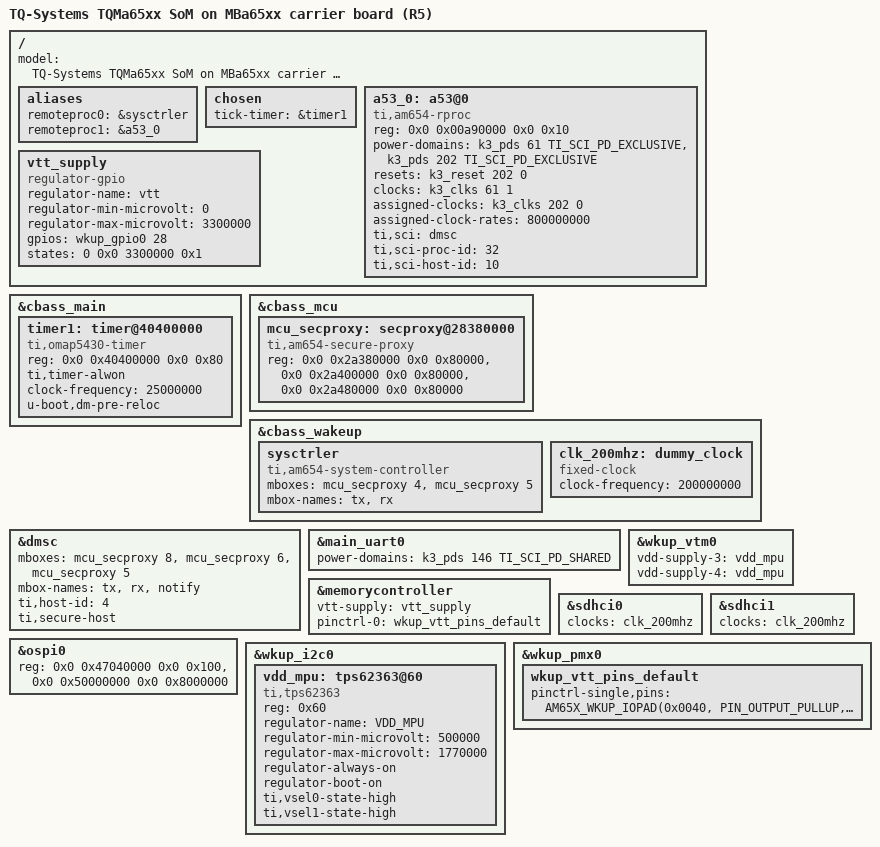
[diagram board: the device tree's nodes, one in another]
// SPDX-License-Identifier: GPL-2.0
/*
 * Copyright (C) 2016-2018 Texas Instruments Incorporated - http://www.ti.com/
 * Copyright (C) 2020-2022 TQ-Systems GmbH
 */

#include "k3-am654-ddr.dtsi"
#include "k3-am654-tqma65xx-mba65xx-u-boot.dtsi"

/ {
	model = "TQ-Systems TQMa65xx SoM on MBa65xx carrier board (R5)";

	aliases {
		remoteproc0 = &sysctrler;
		remoteproc1 = &a53_0;
	};

	chosen {
		tick-timer = &timer1;
	};

	a53_0: a53@0 {
		compatible = "ti,am654-rproc";
		reg = <0x0 0x00a90000 0x0 0x10>;
		power-domains = <&k3_pds 61 TI_SCI_PD_EXCLUSIVE>,
				<&k3_pds 202 TI_SCI_PD_EXCLUSIVE>;
		resets = <&k3_reset 202 0>;
		clocks = <&k3_clks 61 1>;
		assigned-clocks = <&k3_clks 202 0>;
		assigned-clock-rates = <800000000>;
		ti,sci = <&dmsc>;
		ti,sci-proc-id = <32>;
		ti,sci-host-id = <10>;
		u-boot,dm-spl;
	};

	vtt_supply: vtt_supply {
		compatible = "regulator-gpio";
		regulator-name = "vtt";
		regulator-min-microvolt = <0>;
		regulator-max-microvolt = <3300000>;
		gpios = <&wkup_gpio0 28 GPIO_ACTIVE_HIGH>;
		states = <0 0x0 3300000 0x1>;
		u-boot,dm-spl;
	};
};

&cbass_main {
	timer1: timer@40400000 {
		compatible = "ti,omap5430-timer";
		reg = <0x0 0x40400000 0x0 0x80>;
		ti,timer-alwon;
		clock-frequency = <25000000>;
		u-boot,dm-pre-reloc;
	};
};

&cbass_mcu {
	mcu_secproxy: secproxy@28380000 {
		compatible = "ti,am654-secure-proxy";
		reg = <0x0 0x2a380000 0x0 0x80000>,
		      <0x0 0x2a400000 0x0 0x80000>,
		      <0x0 0x2a480000 0x0 0x80000>;
		reg-names = "rt", "scfg", "target_data";
		#mbox-cells = <1>;
		u-boot,dm-spl;
	};
};

&cbass_wakeup {
	sysctrler: sysctrler {
		compatible = "ti,am654-system-controller";
		mboxes= <&mcu_secproxy 4>, <&mcu_secproxy 5>;
		mbox-names = "tx", "rx";
		u-boot,dm-spl;
	};

	clk_200mhz: dummy_clock {
		compatible = "fixed-clock";
		#clock-cells = <0>;
		clock-frequency = <200000000>;
		u-boot,dm-spl;
	};
};

&dmsc {
	mboxes = <&mcu_secproxy 8>, <&mcu_secproxy 6>, <&mcu_secproxy 5>;
	mbox-names = "tx", "rx", "notify";
	ti,host-id = <4>;
	ti,secure-host;
};

&main_uart0 {
	power-domains = <&k3_pds 146 TI_SCI_PD_SHARED>;
};

&wkup_vtm0 {
	vdd-supply-3 = <&vdd_mpu>;
	vdd-supply-4 = <&vdd_mpu>;
	u-boot,dm-spl;
};

&memorycontroller {
	vtt-supply = <&vtt_supply>;
	pinctrl-names = "default";
	pinctrl-0 = <&wkup_vtt_pins_default>;
};

&sdhci0 {
	clock-names = "clk_xin";
	clocks = <&clk_200mhz>;
	/delete-property/ power-domains;
};

&sdhci1 {
	clock-names = "clk_xin";
	clocks = <&clk_200mhz>;
	/delete-property/ power-domains;
};

&ospi0 {
	reg = <0x0 0x47040000 0x0 0x100>,
	      <0x0 0x50000000 0x0 0x8000000>;
};

&wkup_i2c0 {
	vdd_mpu: tps62363@60 {
		compatible = "ti,tps62363";
		reg = <0x60>;
		regulator-name = "VDD_MPU";
		regulator-min-microvolt = <500000>;
		regulator-max-microvolt = <1770000>;
		regulator-always-on;
		regulator-boot-on;
		ti,vsel0-state-high;
		ti,vsel1-state-high;
		u-boot,dm-spl;
	};
};

&wkup_pmx0 {
	wkup_vtt_pins_default: wkup_vtt_pins_default {
		pinctrl-single,pins = <
			/* WKUP_GPIO0_28 */
			AM65X_WKUP_IOPAD(0x0040, PIN_OUTPUT_PULLUP, 7)
		>;
		u-boot,dm-spl;
	};
};
